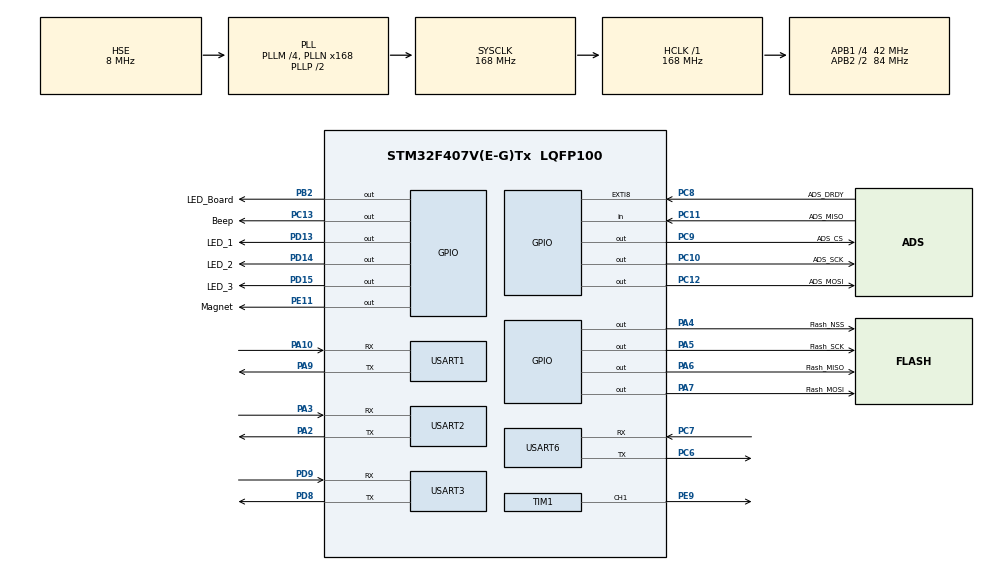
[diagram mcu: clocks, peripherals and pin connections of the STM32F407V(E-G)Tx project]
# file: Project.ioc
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Dma.Request0=USART2_RX
Dma.Request1=USART3_RX
Dma.Request2=USART6_RX
Dma.USART2_RX.0.Direction=DMA_PERIPH_TO_MEMORY
Dma.USART2_RX.0.FIFOMode=DMA_FIFOMODE_DISABLE
Dma.USART2_RX.0.Instance=DMA1_Stream5
Dma.USART2_RX.0.MemDataAlignment=DMA_MDATAALIGN_BYTE
Dma.USART2_RX.0.MemInc=DMA_MINC_ENABLE
Dma.USART2_RX.0.Mode=DMA_NORMAL
Dma.USART2_RX.0.PeriphDataAlignment=DMA_PDATAALIGN_BYTE
Dma.USART2_RX.0.PeriphInc=DMA_PINC_DISABLE
Dma.USART2_RX.0.Priority=DMA_PRIORITY_LOW
Dma.USART3_RX.1.Direction=DMA_PERIPH_TO_MEMORY
Dma.USART3_RX.1.FIFOMode=DMA_FIFOMODE_DISABLE
Dma.USART3_RX.1.Instance=DMA1_Stream1
Dma.USART3_RX.1.MemDataAlignment=DMA_MDATAALIGN_BYTE
Dma.USART3_RX.1.MemInc=DMA_MINC_ENABLE
Dma.USART3_RX.1.Mode=DMA_NORMAL
Dma.USART3_RX.1.PeriphDataAlignment=DMA_PDATAALIGN_BYTE
Dma.USART3_RX.1.PeriphInc=DMA_PINC_DISABLE
Dma.USART3_RX.1.Priority=DMA_PRIORITY_LOW
Dma.USART6_RX.2.Direction=DMA_PERIPH_TO_MEMORY
Dma.USART6_RX.2.FIFOMode=DMA_FIFOMODE_DISABLE
Dma.USART6_RX.2.Instance=DMA2_Stream1
Dma.USART6_RX.2.MemDataAlignment=DMA_MDATAALIGN_BYTE
Dma.USART6_RX.2.MemInc=DMA_MINC_ENABLE
Dma.USART6_RX.2.Mode=DMA_NORMAL
Dma.USART6_RX.2.PeriphDataAlignment=DMA_PDATAALIGN_BYTE
Dma.USART6_RX.2.PeriphInc=DMA_PINC_DISABLE
Dma.USART6_RX.2.Priority=DMA_PRIORITY_LOW
Mcu.Family=STM32F4
Mcu.Name=STM32F407V(E-G)Tx
Mcu.Package=LQFP100
NVIC.DMA1_Stream1_IRQn=true\:0\:0\:false\:false\:true\:false\:true\:true
NVIC.DMA1_Stream5_IRQn=true\:0\:0\:false\:false\:true\:false\:true\:true
NVIC.DMA2_Stream1_IRQn=true\:0\:0\:false\:false\:true\:false\:true\:true
NVIC.EXTI9_5_IRQn=true\:0\:0\:true\:false\:true\:true\:true\:true
NVIC.PriorityGroup=NVIC_PRIORITYGROUP_2
NVIC.TIM2_IRQn=true\:0\:0\:false\:false\:true\:true\:true\:true
NVIC.TIM3_IRQn=true\:1\:0\:true\:false\:true\:true\:true\:true
NVIC.TIM4_IRQn=true\:2\:0\:true\:false\:true\:true\:true\:true
NVIC.USART2_IRQn=true\:0\:0\:false\:false\:true\:true\:true\:true
NVIC.USART3_IRQn=true\:0\:0\:false\:false\:true\:true\:true\:true
NVIC.USART6_IRQn=true\:0\:0\:false\:false\:true\:true\:true\:true
PA10.Mode=Asynchronous
PA10.Signal=USART1_RX
PA13.Mode=Serial_Wire
PA13.Signal=SYS_JTMS-SWDIO
PA14.Mode=Serial_Wire
PA14.Signal=SYS_JTCK-SWCLK
PA2.Mode=Asynchronous
PA2.Signal=USART2_TX
PA3.Mode=Asynchronous
PA3.Signal=USART2_RX
PA4.GPIO_Label=Flash_NSS
PA4.Signal=GPIO_Output
PA5.GPIO_Label=Flash_SCK
PA5.Signal=GPIO_Output
PA6.GPIO_Label=Flash_MISO
PA6.Signal=GPIO_Output
PA7.GPIO_Label=Flash_MOSI
PA7.Signal=GPIO_Output
PA9.Mode=Asynchronous
PA9.Signal=USART1_TX
PB2.GPIO_Label=LED_Board
PB2.Signal=GPIO_Output
PC10.GPIO_Label=ADS_SCK
PC10.Signal=GPIO_Output
PC11.GPIO_Label=ADS_MISO
PC11.Signal=GPIO_Input
PC12.GPIO_Label=ADS_MOSI
PC12.Signal=GPIO_Output
PC13-ANTI_TAMP.GPIO_Label=Beep
PC13-ANTI_TAMP.Signal=GPIO_Output
PC6.Mode=Asynchronous
PC6.Signal=USART6_TX
PC7.Mode=Asynchronous
PC7.Signal=USART6_RX
PC8.GPIO_Label=ADS_DRDY
PC8.GPIO_ModeDefaultEXTI=GPIO_MODE_IT_FALLING
PC8.GPIO_PuPd=GPIO_PULLUP
PC8.Signal=GPXTI8
PC9.GPIO_Label=ADS_CS
PC9.Signal=GPIO_Output
PD13.GPIO_Label=LED_1
PD13.Signal=GPIO_Output
PD14.GPIO_Label=LED_2
PD14.Signal=GPIO_Output
PD15.GPIO_Label=LED_3
PD15.Signal=GPIO_Output
PD8.Mode=Asynchronous
PD8.Signal=USART3_TX
PD9.Mode=Asynchronous
PD9.Signal=USART3_RX
PE11.GPIO_Label=Magnet
PE11.Signal=GPIO_Output
PE9.Signal=S_TIM1_CH1
PH0-OSC_IN.Mode=HSE-External-Oscillator
PH0-OSC_IN.Signal=RCC_OSC_IN
PH1-OSC_OUT.Mode=HSE-External-Oscillator
PH1-OSC_OUT.Signal=RCC_OSC_OUT
ProjectManager.HeapSize=0x200
ProjectManager.StackSize=0x400
ProjectManager.TargetToolchain=MDK-ARM V5.32
RCC.48MHZClocksFreq_Value=84000000
RCC.AHBFreq_Value=168000000
RCC.APB1CLKDivider=RCC_HCLK_DIV4
RCC.APB1Freq_Value=42000000
RCC.APB1TimFreq_Value=84000000
RCC.APB2CLKDivider=RCC_HCLK_DIV2
RCC.APB2Freq_Value=84000000
RCC.APB2TimFreq_Value=168000000
RCC.CortexFreq_Value=168000000
RCC.HCLKFreq_Value=168000000
RCC.HSE_VALUE=8000000
RCC.HSI_VALUE=16000000
RCC.LSE_VALUE=32768
RCC.PLLM=4
RCC.PLLN=168
RCC.PLLSourceVirtual=RCC_PLLSOURCE_HSE
RCC.SYSCLKFreq_VALUE=168000000
RCC.SYSCLKSource=RCC_SYSCLKSOURCE_PLLCLK
RCC.VCOOutputFreq_Value=336000000
SH.S_TIM1_CH1.0=TIM1_CH1,PWM Generation1 CH1
TIM1.AutoReloadPreload=TIM_AUTORELOAD_PRELOAD_ENABLE
TIM1.Channel-PWM\ Generation1\ CH1=TIM_CHANNEL_1
TIM1.Period=20000-1
TIM1.Prescaler=168-1
TIM2.Period=10000
TIM2.Prescaler=84-1
TIM3.Period=1000-1
TIM3.Prescaler=84-1
TIM4.Period=5000
TIM4.Prescaler=8400-1
USART1.VirtualMode=VM_ASYNC
USART2.VirtualMode=VM_ASYNC
USART3.VirtualMode=VM_ASYNC
USART6.VirtualMode=VM_ASYNC
VP_TIM1_VS_ClockSourceINT.Mode=Internal
VP_TIM2_VS_ClockSourceINT.Mode=Internal
VP_TIM3_VS_ClockSourceINT.Mode=Internal
VP_TIM4_VS_ClockSourceINT.Mode=Internal
board=custom

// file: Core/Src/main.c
/* USER CODE BEGIN Header */
/**
  ******************************************************************************
  * @file           : main.c
  * @brief          : Main program body
  ******************************************************************************
  * @attention
  *
  * Copyright (c) 2025 STMicroelectronics.
  * All rights reserved.
  *
  * This software is licensed under terms that can be found in the LICENSE file
  * in the root directory of this software component.
  * If no LICENSE file comes with this software, it is provided AS-IS.
  *
  ******************************************************************************
  */
/* USER CODE END Header */
#include "main.h"
#include "dma.h"
#include "tim.h"
#include "usart.h"
#include "gpio.h"

/* USER CODE BEGIN Includes */
#include "hardware_config.h"
#include "ads1220.h"
/* USER CODE END Includes */

void SystemClock_Config(void);

/* USER CODE BEGIN 0 */
int16_t count = 0;
/* USER CODE END 0 */

int main(void)
{

  /* MCU Configuration--------------------------------------------------------*/

  /* Reset of all peripherals, Initializes the Flash interface and the Systick. */
  HAL_Init();

  /* Configure the system clock */
  SystemClock_Config();

  /* Initialize all configured peripherals */
  MX_GPIO_Init();
  MX_DMA_Init();
  MX_TIM1_Init();
  MX_USART1_UART_Init();
  MX_USART2_UART_Init();
  MX_USART3_UART_Init();
  MX_USART6_UART_Init();
  MX_TIM2_Init();
  MX_TIM3_Init();
  MX_TIM4_Init();
  /* USER CODE BEGIN 2 */
  HardwareConfig();
  ADS1220_Init();
  HAL_Delay(3);
  adc_data = ADS1220_ReadData();
  /* USER CODE END 2 */

  /* Infinite loop */
  /* USER CODE BEGIN WHILE */
  while (1)
  {

//      adc_data = ADS1220_ReadData();
//      HAL_Delay(500);
    /* USER CODE END WHILE */

  }
}

void SystemClock_Config(void)
{
  RCC_OscInitTypeDef RCC_OscInitStruct = {0};
  RCC_ClkInitTypeDef RCC_ClkInitStruct = {0};

  /** Configure the main internal regulator output voltage
  */
  __HAL_RCC_PWR_CLK_ENABLE();
  __HAL_PWR_VOLTAGESCALING_CONFIG(PWR_REGULATOR_VOLTAGE_SCALE1);

  /** Initializes the RCC Oscillators according to the specified parameters
  * in the RCC_OscInitTypeDef structure.
  */
  RCC_OscInitStruct.OscillatorType = RCC_OSCILLATORTYPE_HSE;
  RCC_OscInitStruct.HSEState = RCC_HSE_ON;
  RCC_OscInitStruct.PLL.PLLState = RCC_PLL_ON;
  RCC_OscInitStruct.PLL.PLLSource = RCC_PLLSOURCE_HSE;
  RCC_OscInitStruct.PLL.PLLM = 4;
  RCC_OscInitStruct.PLL.PLLN = 168;
  RCC_OscInitStruct.PLL.PLLP = RCC_PLLP_DIV2;
  RCC_OscInitStruct.PLL.PLLQ = 4;
  if (HAL_RCC_OscConfig(&RCC_OscInitStruct) != HAL_OK)
  {
    Error_Handler();
  }

  /** Initializes the CPU, AHB and APB buses clocks
  */
  RCC_ClkInitStruct.ClockType = RCC_CLOCKTYPE_HCLK|RCC_CLOCKTYPE_SYSCLK
                              |RCC_CLOCKTYPE_PCLK1|RCC_CLOCKTYPE_PCLK2;
  RCC_ClkInitStruct.SYSCLKSource = RCC_SYSCLKSOURCE_PLLCLK;
  RCC_ClkInitStruct.AHBCLKDivider = RCC_SYSCLK_DIV1;
  RCC_ClkInitStruct.APB1CLKDivider = RCC_HCLK_DIV4;
  RCC_ClkInitStruct.APB2CLKDivider = RCC_HCLK_DIV2;

  if (HAL_RCC_ClockConfig(&RCC_ClkInitStruct, FLASH_LATENCY_5) != HAL_OK)
  {
    Error_Handler();
  }
}

void Error_Handler(void)
{
  __disable_irq();
  while (1)
  {
  }
}
